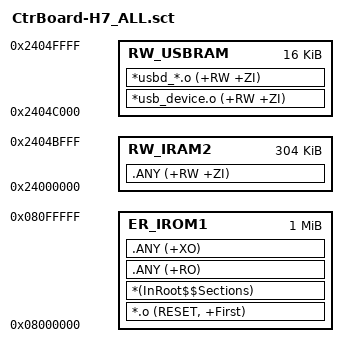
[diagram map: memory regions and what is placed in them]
LR_IROM1 0x08000000 0x00100000  {    ; load region size_region
  ER_IROM1 0x08000000 0x00100000  {  ; load address = execution address
   *.o (RESET, +First)
   *(InRoot$$Sections)
   .ANY (+RO)
   .ANY (+XO)
  }
  RW_USBRAM 0x2404C000 0x00004000  {
   *usb_device.o (+RW +ZI)
   *usbd_*.o (+RW +ZI)
  }
  RW_IRAM2 0x24000000 0x0004C000  {
   .ANY (+RW +ZI)
  }
}

